# STM32H7S register map
File version: 1.3
CPU: CM7 r0p1, little endian, MPU, FPU, 4 interrupt priority bits
Registers are 32-bit, read-write, reset 0x0 unless marked. A register's access mark holds for its fields unless they carry their own. Offsets are from the block's base; [hi:lo] are bit positions; 'fields as' and 'values as' point back to an identical list.

## DCMIPP — Digital camera interface pixel pipeline
Base 0x50002000
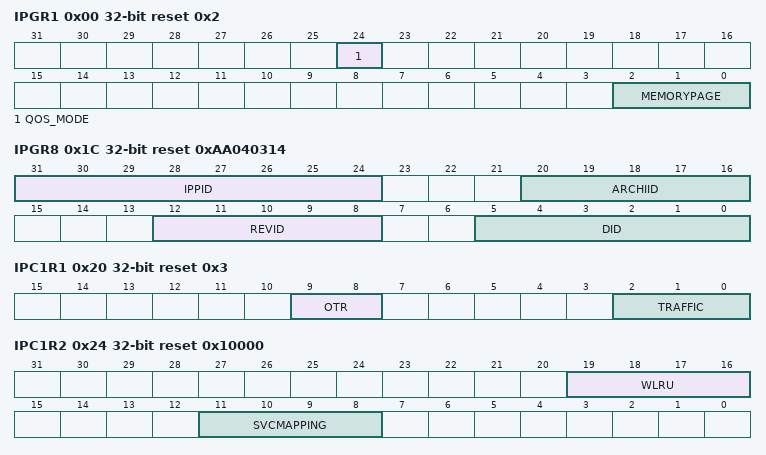
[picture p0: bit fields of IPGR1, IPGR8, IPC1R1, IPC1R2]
0x00 IPGR1 reset 0x2 — DCMIPP IP-Plug global register 1
  [24] QOS_MODE — Quality of service Set of functions enabling to build and configure an architecture able to meet bandwidth and latency requirements.
  [2:0] MEMORYPAGE — Memory page size, as power of 2 of 64-byte units:
0x04 IPGR2 — DCMIPP IP-Plug global register 2
  [0] PSTART — Request to lock the IP-Plug, to allow reconfiguration. PSTART must be reset to 0 after configuration is completed, to restart the IP-Plug.
0x08 IPGR3 ro reset 0x1 — DCMIPP IP-Plug global register 3
  [0] IDLE — Status of IP-Plug IDLE is set some time after a request by setting PSTART at 1, and reset by resetting PSTART at 0.
0x1C IPGR8 ro reset 0xAA040314 — DCMIPP IP-Plug identification register
  [31:24] IPPID — IP identifier (0xAA)
  [20:16] ARCHIID — Architecture identifier (0x04)
  [12:8] REVID — Revision identifier (0x03)
  [5:0] DID — Division identifier (0x14)
0x20 IPC1R1 reset 0x3 — DCMIPP IP-Plug Clientx register 1
  [9:8] OTR — Maximum outstanding transactions ... Other values are not allowed.
  [2:0] TRAFFIC — Burst size as power of 2 of 8-byte units Other values: Reserved
0x24 IPC1R2 reset 0x10000 — DCMIPP IP-Plug Clientx register 2
  [19:16] WLRU — Ratio for WLRU[3:0] arbitration A client gets a portion of the total bandwidth = Ratio(client) / Sum(all ratio) ...
  [11:8] SVCMAPPING — Non-user, must be kept at reset value.
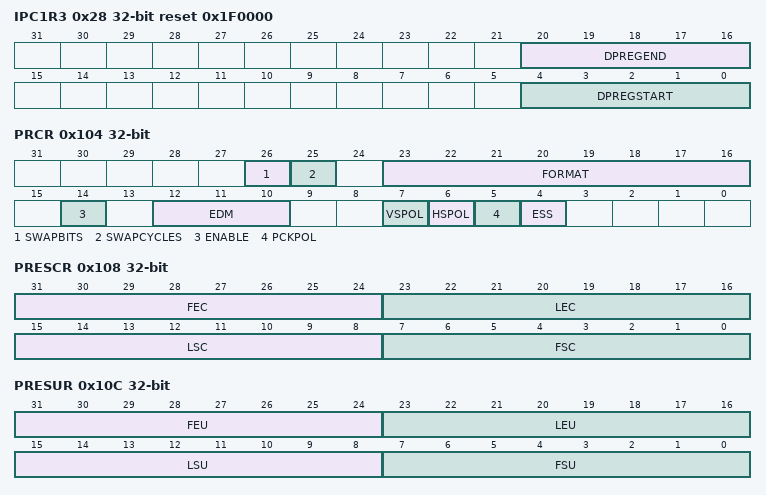
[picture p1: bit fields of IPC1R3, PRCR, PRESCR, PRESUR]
0x28 IPC1R3 reset 0x1F0000 — DCMIPP IP-Plug Clientx register 3
  [20:16] DPREGEND — End word (AXI width = 64 bits) of the FIFO of Clientx. The addressed word is included in the FIFO, so that next DPREGSTART is DPREGEND + 1.
  [4:0] DPREGSTART — Start word (AXI width = 64 bits) of the FIFO of Clientx.
0x104 PRCR — DCMIPP parallel interface control register
  [26] SWAPBITS — Swap LSB vs. MSB within each received component
  [25] SWAPCYCLES — Swap data (cycle 0 vs. cycle 1) for pixels received on two cycles The swap must not be activated by software for pixels received in one or three cycles.
  [23:16] FORMAT — Other values: data are captured and output as-is only through the data/dump pipeline (for example JPEG or byte input format). The monochrome Y input is inserted in the pipe as YUV pixels, with the U and V components set to neutral, to represent a grey color.
  [14] ENABLE — Parallel interface enable The parallel interface configuration registers must be correctly programmed before enabling this bit.
  [12:10] EDM — Extended data mode Other values: Reserved.
  [7] VSPOL — Vertical synchronization polarity This bit indicates the level on the VSYNC pin when the data are not valid on the parallel interface.
  [6] HSPOL — Horizontal synchronization polarity This bit indicates the level on the HSYNC pin when the data are not valid on the parallel interface.
  [5] PCKPOL — Pixel clock polarity This bit configures the capture edge of the pixel clock
  [4] ESS — Embedded synchronization select Valid only for 8-bit parallel data. HSPOL/VSPOL are ignored when this bit is set.
0x108 PRESCR — DCMIPP parallel interface embedded synchronization code register
  [31:24] FEC — Frame end delimiter code This byte specifies the code of the frame end delimiter. The code consists of four bytes in the form of 0xFF, 0x00, 0x00, FEC. If FEC is programmed to 0xFF, all the unused codes (0xFF00 00XY) are interpreted as frame end delimiters.
  [23:16] LEC — Line end delimiter code This byte specifies the code of the line end delimiter. The code consists of four bytes in the form of 0xFF, 0x00, 0x00, LEC.
  [15:8] LSC — Line start delimiter code This byte specifies the code of the line start delimiter. The code consists of four bytes in the form of 0xFF, 0x00, 0x00, LSC.
  [7:0] FSC — Frame start delimiter code This byte specifies the code of the frame start delimiter. The code consists of four bytes in the form of 0xFF, 0x00, 0x00, FSC. If FSC is programmed to 0xFF, no frame start delimiter is detected, but the first occurrence of LSC after an FEC code is interpreted as the start of frame delimiter.
0x10C PRESUR — DCMIPP parallel interface embedded synchronization unmask register
  [31:24] FEU — Frame end delimiter unmask This byte specifies the mask to be applied to the code of the frame end delimiter.
  [23:16] LEU — Line end delimiter unmask This byte specifies the mask to be applied to the code of the line end delimiter.
  [15:8] LSU — Line start delimiter unmask This byte specifies the mask to be applied to the code of the line start delimiter.
  [7:0] FSU — Frame start delimiter unmask This byte specifies the mask to be applied to the code of the frame start delimiter.
0x1F4 PRIER — DCMIPP parallel interface interrupt enable register
  [6] ERRIE — Synchronization error interrupt enable This bit is available only in embedded synchronization mode.
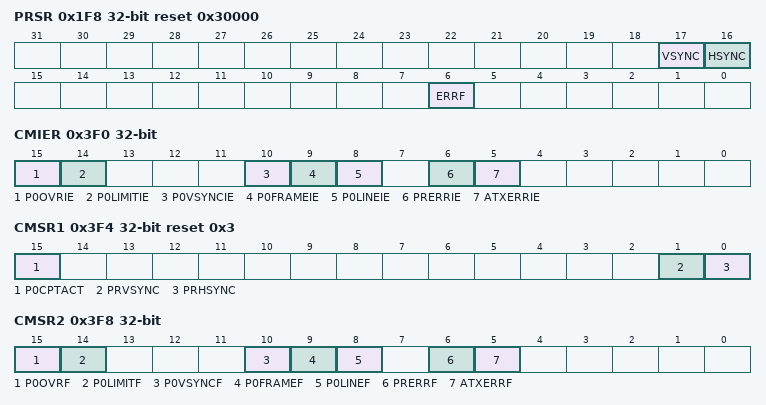
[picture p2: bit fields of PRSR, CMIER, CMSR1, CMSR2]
0x1F8 PRSR ro reset 0x30000 — DCMIPP parallel interface status register
  [17] VSYNC — This bit gives the state of the VSYNC pin with the correct programmed polarity if ENABLE bit is set into the DCMIPP_PRCR register and if the pixel clock is received. It is set during the blanking period whatever the polarity selected in VPOL bit, and cleared otherwise. When embedded synchronization codes are used: In case of embedded synchronization, this bit is meaningful only if the CAPTURE bit in DCMIPP_CR is set.
  [16] HSYNC — This bit gives the state of the HSYNC pin with the correct programmed polarity if ENABLE bit is set into the DCMIPP_PRCR register and if the pixel clock is received. It is set during the blanking period whatever the polarity selected in HPOL bit, and cleared otherwise. When embedded synchronization codes are used: In case of embedded synchronization, this bit is meaningful only if the CAPTURE bit in DCMIPP_CR is set.
  [6] ERRF — Synchronization error raw interrupt status This bit is valid only in the embedded synchronization mode. It is cleared by writing a 1 to the CERRF bit in DCMIPP_PRFCR. This bit is available only in embedded synchronization mode.
0x1FC PRFCR wo — DCMIPP parallel interface interrupt clear register
  [6] CERRF — Synchronization error interrupt status clear Writing a 1 into this bit clears the ERRF bit in DCMIPP_PRSR. This bit is available only in embedded synchronization mode.
0x204 CMCR wo — DCMIPP common configuration register
  [4] CFC — Clear frame counter When this bit is set, the frame counter associated to a pipe is cleared. It resets DCMIPP_CMFRCR register. This bit is always read at 0.
0x208 CMFRCR ro — DCMIPP common frame counter register
  [31:0] FRMCNT — Frame counter, read-only, loops around. Incremented following VSYNC detection mapped to the pipe configured into bits PSFC[1:0] of the DCMIPP_CMCR register. The counter is cleared using the CRC bit in the DCMIPP_CMCR register.
0x3F0 CMIER — DCMIPP common interrupt enable register
  [15] P0OVRIE — Overrun interrupt enable for Pipe0
  [14] P0LIMITIE — Limit interrupt enable for Pipe0
  [10] P0VSYNCIE — Vertical sync interrupt enable for Pipe0
  [9] P0FRAMEIE — Frame capture complete interrupt enable for Pipe0
  [8] P0LINEIE — Multi-line capture complete interrupt enable for Pipe0
  [6] PRERRIE — Limit interrupt enable for the parallel Interface
  [5] ATXERRIE — AXI transfer error interrupt enable for IP-Plug
0x3F4 CMSR1 ro reset 0x3 — DCMIPP common status register 1
  [15] P0CPTACT — Active frame capture (active from start-of-frame to frame complete) for Pipe0
  [1] PRVSYNC — This bit gives the state of the VSYNC pin with the correct programmed polarity on the parallel interface if ENABLE bit is set into the DCMIPP_PRCR register and if the pixel clock is received. It is set during the blanking period whatever the polarity selected in VPOL bit of the DCMIPP_PRCR register, and cleared otherwise. When embedded synchronization codes are used, the meaning of this bit is the following: In case of embedded synchronization, this bit is meaningful only if the CAPTURE bit in the DCMIPP_PRCR register is set.
  [0] PRHSYNC — This bit gives the state of the HSYNC pin with the correct programmed polarity on the parallel interface if ENABLE bit is set into the DCMIPP_PRCR register and if the pixel clock is received. It is set during the blanking period whatever the polarity selected in HPOL bit of the DCMIPP_PRCR register, and cleared otherwise. When embedded synchronization codes are used the meaning of this bit is the following: In case of embedded synchronization, this bit is meaningful only if the CAPTURE bit in the DCMIPP_PRCR register is set.
0x3F8 CMSR2 ro — DCMIPP common status register 2
  [15] P0OVRF — Overrun raw interrupt status for Pipe0 This bit is cleared by writing a 1 to the CP0OVRF bit in the DCMIPP_CMFCR register.
  [14] P0LIMITF — Limit raw interrupt status for Pipe0 This bit is set when the data counter DCMIPP_P0DCCNT reaches its maximum value DCMIPP_P0DCLIMIT. It is cleared by writing a 1 to the CP0LIMITF bit in the DCMIPP_CMFCR register.
  [10] P0VSYNCF — VSYNC raw interrupt status for Pipe0 This bit is set when the VSYNC signal changes from the inactive state to the active state. In the case of embedded synchronization, this bit is set only if the CAPTURE bit is set in DCMIPP_CR. It is cleared by writing a 1 to the CP0VSYNCF bit in the DCMIPP_CMFCR register.
  [9] P0FRAMEF — Frame capture completed raw interrupt status for Pipe0 This bit is set when all data of a frame or window have been captured. In case of a cropped window, this bit is set at the end of line of the last line in the crop, even if the captured frame is empty (for example window cropped outside the frame). This bit is cleared by writing a 1 to the CP0FRAMEF bit in the DCMIPP_CMFCR register.
  [8] P0LINEF — Multi-line capture completed raw interrupt status for Pipe0 This bit is set when one/more lines have been completed. The periodicity of LINEF event is configured by LINEMULT bits into DCMIPP_P0PPCR register. When reaching end of frame, this event is triggered out to allow software action even if the LINEMULT value set is not a multiple of the total lines frame. In the case of embedded synchronization, this bit is set only if the CAPTURE bit in the DCMIPP_CR register is set. It is cleared by writing a 1 to the CP0LINEF bit in the DCMIPP_CMFCR register.
  [6] PRERRF — Synchronization error raw interrupt status for the parallel interface. This bit is valid only in the embedded synchronization mode. It is cleared by writing a 1 to the CPRERRF bit in the DCMIPP_CMFCR register. This bit is available only in embedded synchronization mode.
  [5] ATXERRF — AXI transfer error interrupt status flag for the IP-Plug. This bit is cleared by writing a 1 to CATXERRF bit in the DCMIPP_CMFCR register.
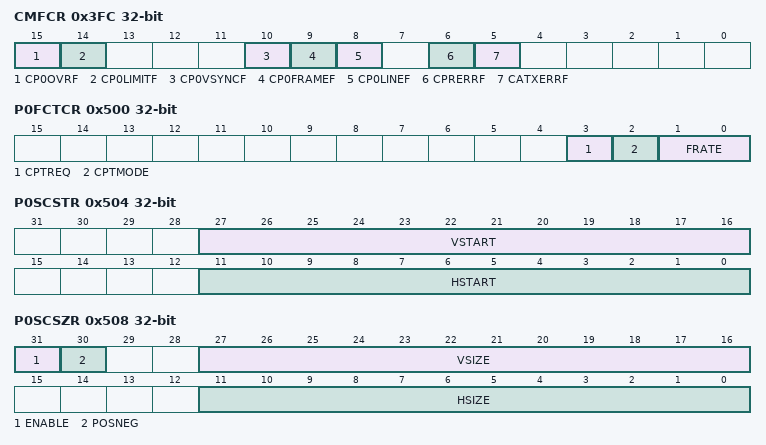
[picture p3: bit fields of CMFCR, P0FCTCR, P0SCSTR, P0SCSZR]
0x3FC CMFCR wo — DCMIPP common interrupt clear register
  [15] CP0OVRF — Overrun interrupt status clear Writing a 1 into this bit clears the P0OVRF bit in the DCMIPP_CMSR2 register
  [14] CP0LIMITF — limit interrupt status clear Writing a 1 into this bit clears P0LIMITF in the DCMIPP_CMSR2 register
  [10] CP0VSYNCF — Vertical synchronization interrupt status clear Writing a 1 into this bit clears the P0VSYNCF bit in the DCMIPP_CMSR2 register.
  [9] CP0FRAMEF — Frame capture complete interrupt status clear Writing a 1 into this bit clears the P0FRAMEF bit in the DCMIPP_CMSR2 register.
  [8] CP0LINEF — Multi-line capture complete interrupt status clear Writing a 1 into this bit clears P0LINEF in the DCMIPP_CMSR2 register
  [6] CPRERRF — Synchronization error interrupt status clear Writing a 1 into this bit clears the PRERRF bit in the DCMIPP_CMSR2 register. This bit is available only in embedded synchronization mode.
  [5] CATXERRF — AXI transfer error interrupt status clear Writing a 1 into this bit clears the ATXERRF bit in the DCMIPP_CMSR2 register.
0x404 P0FSCR — DCMIPP Pipe0 flow selection configuration register
  [31] PIPEN — Activation of PipeN Note: This bit is not shadowed, differently from all other bits in this register.
0x500 P0FCTCR — DCMIPP Pipe0 flow control configuration register
  [3] CPTREQ — Capture requested When PIPEN = 1 and when the CPTREQ is set to 1 the pipe waits for the first VSync, and automatically starts a capture and sets CPTACT = 1 to mention it. In Snapshot mode the CPTREQ bit is automatically cleared at the start of the first received frame. In Continuous grab mode, the capture remains active and CPTREQ = 1 until the software clears CPTREQ: the capture stops and CPTACT is reset at the end of the ongoing frame. The DCMI and pipe configuration registers must be correctly programmed before enabling this bit.
  [2] CPTMODE — Capture mode
  [1:0] FRATE — Frame capture rate control These bits define the frequency of frame capture. They are meaningful only in Continuous grab mode, ignored in Snapshot mode.
0x504 P0SCSTR — DCMIPP Pipe0 stat/crop start register
  [27:16] VSTART — Vertical start, from 0 to 4094 pixels high
  [11:0] HSTART — Horizontal start, from 0 to 4094 words wide
0x508 P0SCSZR — DCMIPP Pipe0 stat/crop size register
  [31] ENABLE — This bit is set and cleared by software. if POSNEG = 0, the data inside the rectangle area are transmitted (it can correspond to a statistical data removal, or as a crop feature in a data valid image area). if POSNEG = 1, the data outside of the rectangle area are transmitted (it can correspond to a statistical data extraction, rejecting all data inside the window). This bit must be kept cleared if the input format is JPEG, to avoid unpredictable behavior of the pipe.
  [30] POSNEG — This bit is set and cleared by software. It has a meaning only if ENABLE bit is set.
  [27:16] VSIZE — Vertical size, from 0 to 4094 pixels high If the value is maintained at 0 when enabling the crop by means of ENABLE bit, the crop operation is not performed on vertical direction.
  [11:0] HSIZE — Horizontal size, from 0 to 4094 word wide (data 32-bit) If the value is maintained at 0 when enabling the crop by means of ENABLE bit, the crop operation is not performed on horizontal direction.
0x5B0 P0DCCNTR ro — DCMIPP Pipe0 dump counter register
  [25:0] CNT — Number of data dumped during the frame. The size of the data is expressed in bytes. It counts only the data selected by means of the CROP 2D function. The counter saturates at 0x3FFFFFF. Granularity is 32-bit for all the formats except for the byte stream formats (for example JPEG) having byte granularity.
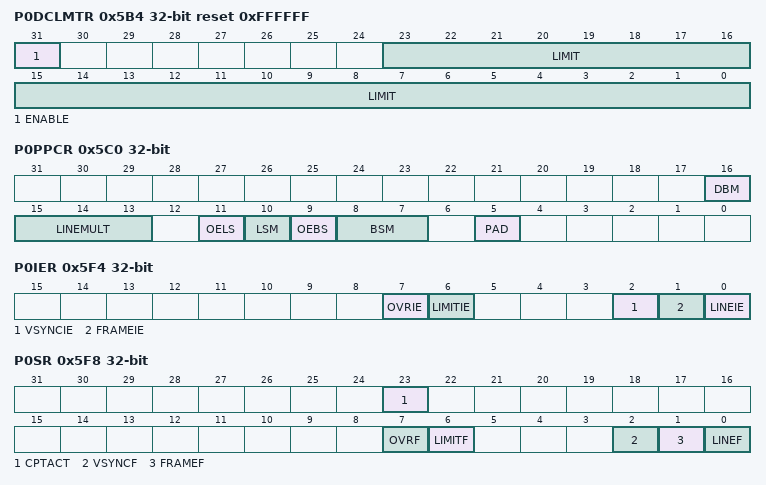
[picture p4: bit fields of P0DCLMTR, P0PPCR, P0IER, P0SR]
0x5B4 P0DCLMTR reset 0xFFFFFF — DCMIPP Pipe0 dump limit register
  [31] ENABLE
  [23:0] LIMIT — Maximum number of 32-bit data that can be dumped during a frame, after the crop 2D operation.
0x5C0 P0PPCR — DCMIPP Pipe0 pixel packer configuration register
  [16] DBM — Double buffer mode This bit is set and cleared by software.
  [15:13] LINEMULT — Amount of capture completed lines for LINE event and interrupt
  [11] OELS — Odd/even line select (line select start) This bit works in conjunction with LSM field (LSM = 1).
  [10] LSM — Line select mode
  [9] OEBS — Odd/even byte select (byte select start) This bit works in conjunction with BSM field (BSM different from 00)
  [8:7] BSM — Byte select mode Modes 10 and 11 work only with EDM [2:0] = 000 into the DCMIPP_PRCR register.
  [5] PAD — Pad mode for monochrome and raw Bayer 10/12/14 bpp: MSB vs. LSB alignment.
0x5C4 P0PPM0AR1 — DCMIPP Pipe0 pixel packer Memory0 address register 1
  [31:0] M0A — Memory0 address Base address of memory area 0, to whom data are written. It is assumed to be a multiple of 16, hence its bits 3:0 are always at 0x0.
0x5C8 P0PPM0AR2 — DCMIPP Pipe0 pixel packer Memory0 address register 2
  fields as P0PPM0AR1
0x5F4 P0IER — DCMIPP Pipe0 interrupt enable register
  [7] OVRIE — Overrun interrupt enable
  [6] LIMITIE — Limit interrupt enable
  [2] VSYNCIE — VSYNC interrupt enable
  [1] FRAMEIE — Frame capture completed interrupt enable
  [0] LINEIE — Multi-line capture completed interrupt enable
0x5F8 P0SR ro — DCMIPP Pipe0 status register
  [23] CPTACT — Capture immediate status This bit is automatically reset at the end of frame capture complete event (after all the data of that frame have been captured and the IP-Plug has started to emit the last burst on the AXI, usually before the next VSync).
  [7] OVRF — Overrun raw interrupt status This bit is cleared by writing a 1 to the COVRF bit in the DCMIPP_P0FCR register.
  [6] LIMITF — Limit raw interrupt status This bit is set when the data counter DCMIPP_PxDCCNTR reaches its maximum value DCMIPP_PxDCLIMITR. It is cleared by writing a 1 to the CLIMITF bit in the DCMIPP_P0FCR register.
  [2] VSYNCF — VSYNC raw interrupt status This bit is set when the VSYNC signal changes from the inactive state to the active state. In case of embedded synchronization, this bit is set only if the CAPTURE bit is set in DCMIPP_CR. It is cleared by writing a 1 to the CVSYNCF bit in the DCMIPP_P0FCR register.
  [1] FRAMEF — Frame capture completed raw interrupt status This bit is set when all data of a frame or window have been captured. In case of a cropped window, this bit is set at the end of line of the last line in the crop. It is set even if the captured frame is empty (for example window cropped outside the frame). This bit is cleared by writing a 1 to the CFRAMEF bit in DCMIPP_P0FCR.
  [0] LINEF — Multi-line capture completed raw interrupt status This bit is set when one/more lines have been completed. For the JPEG mode, this bit is raised at the end of the frame. The periodicity of LINEF event is configured by LINEMULT bits into DCMIPP_P0PPCR register. When reaching end of frame, this event is triggered out to allow software action even if the LINEMULT value set is not a multiple of the total lines frame. In case of embedded synchronization, this bit is set only if the CAPTURE bit in the DCMIPP_CR register is set. It is cleared by writing a 1 to the CLINEF bit in the DCMIPP_P0FCR register.
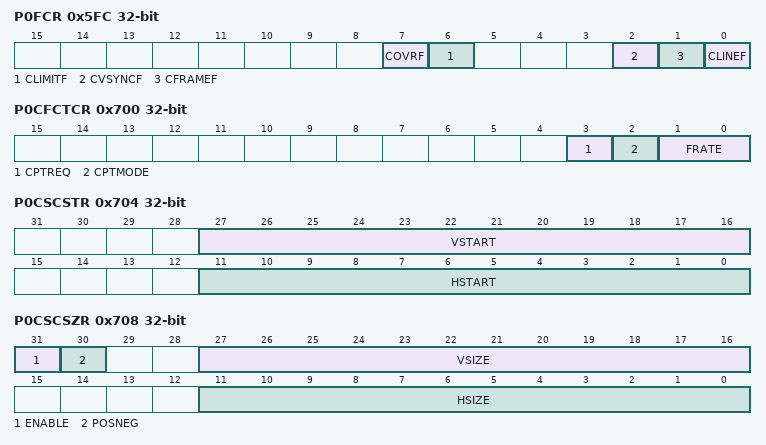
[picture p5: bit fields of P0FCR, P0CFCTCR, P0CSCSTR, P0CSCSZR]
0x5FC P0FCR wo — DCMIPP Pipe0 interrupt clear register
  [7] COVRF — Overrun interrupt status clear Writing a 1 into this bit clears the OVRF bit in the DCMIPP_P0SR register.
  [6] CLIMITF — limit interrupt status clear Writing a 1 into this bit clears LIMITF in the DCMIPP_P0SR register.
  [2] CVSYNCF — Vertical synchronization interrupt status clear Writing a 1 into this bit clears the VSYNCF bit in the DCMIPP_P0SR register.
  [1] CFRAMEF — Frame capture complete interrupt status clear Writing a 1 into this bit clears the FRAMEF bit in the DCMIPP_P0SR register.
  [0] CLINEF — Multi-line capture complete interrupt status clear Writing a 1 into this bit clears LINEF in the DCMIPP_P0SR register.
0x700 P0CFCTCR ro — DCMIPP Pipe0 current flow control configuration register
  [3] CPTREQ — Capture requested When PIPEN = 1, and when the CPTREQ is set to 1 the pipe waits for the first VSync, and automatically starts a capture and sets CPTACT = 1 to mention it. In Snapshot mode the CPTREQ bit is automatically cleared at the start of the first frame received. In continuous grab mode the capture remains active and CPTREQ = 1, until the software clears CPTREQ: the capture stops and CPTACT is reset at the end of the ongoing frame. The DCMI and pipe configuration registers must be correctly programmed before enabling this bit.
  [2] CPTMODE — Capture mode
  [1:0] FRATE — Frame capture rate control These bits define the frequency of frame capture. They are meaningful only in Continuous grab mode, ignored in Snapshot mode.
0x704 P0CSCSTR ro — DCMIPP Pipe0 current stat/crop start register
  [27:16] VSTART — Current vertical start, from 0 to 4094 pixels high
  [11:0] HSTART — Current horizontal start, from 0 to 4094 words wide
0x708 P0CSCSZR ro — DCMIPP Pipe0 current stat/crop size register
  [31] ENABLE — Current value of the ENABLE bit if POSNEG = 0, the data inside the rectangle area are transmitted (can correspond to a statistical data removal, or as a crop feature in a data valid image area). if POSNEG = 1, the data outside of the rectangle area are transmitted (can correspond to a statistical data extraction, rejecting all data inside the window)
  [30] POSNEG — Current value of the POSNEG bit This bit has a meaning only if ENABLE bit is set.
  [27:16] VSIZE — Current vertical size, from 0 to 4094 pixels high. If the value is maintained at 0 when enabling the crop by means of the ENABLE bit, the value is forced internally at 0xFFE which is the maximum value.
  [11:0] HSIZE — Current horizontal size, from 0 to 4094 word wide (data 32-bit). If the value is maintained at 0 when enabling the crop by means of the ENABLE bit, the value is forced internally at 0xFFE, which is the maximum value.
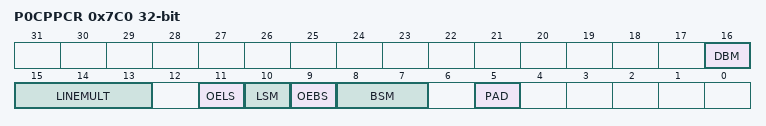
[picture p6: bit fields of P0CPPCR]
0x7C0 P0CPPCR ro — DCMIPP Pipe0 current pixel packer configuration register
  [16] DBM — Double buffer mode
  [15:13] LINEMULT — Current amount of capture completed lines for LINE event and interrupt
  [11] OELS — Current odd/even line select (ine select start) This bit works in conjunction with LSM field (LSM = 1)
  [10] LSM — Current Line select mode
  [9] OEBS — Current odd/even byte select (byte select start) This bit works in conjunction with BSM field (BSM different from 00)
  [8:7] BSM — Current Byte select mode Modes 10 and 11 work only with EDM [2:0] = 000 into the DCMIPP_PRCR register.
  [5] PAD — Current Pad mode for monochrome and raw Bayer 10/12/14 bpp: MSB vs. LSB alignment
0x7C4 P0CPPM0AR1 ro — DCMIPP Pipe0 current pixel packer Memory0 address register 1
  [31:0] M0A — Memory0 address Base address of the current memory area 0, to whom data are written. It is assumed to be a multiple of 16, hence its bits 3:0 are always at 0x0.
0x7C8 P0CPPM0AR2 ro — DCMIPP Pipe0 current pixel packer Memory0 address register 2
  fields as P0CPPM0AR1
